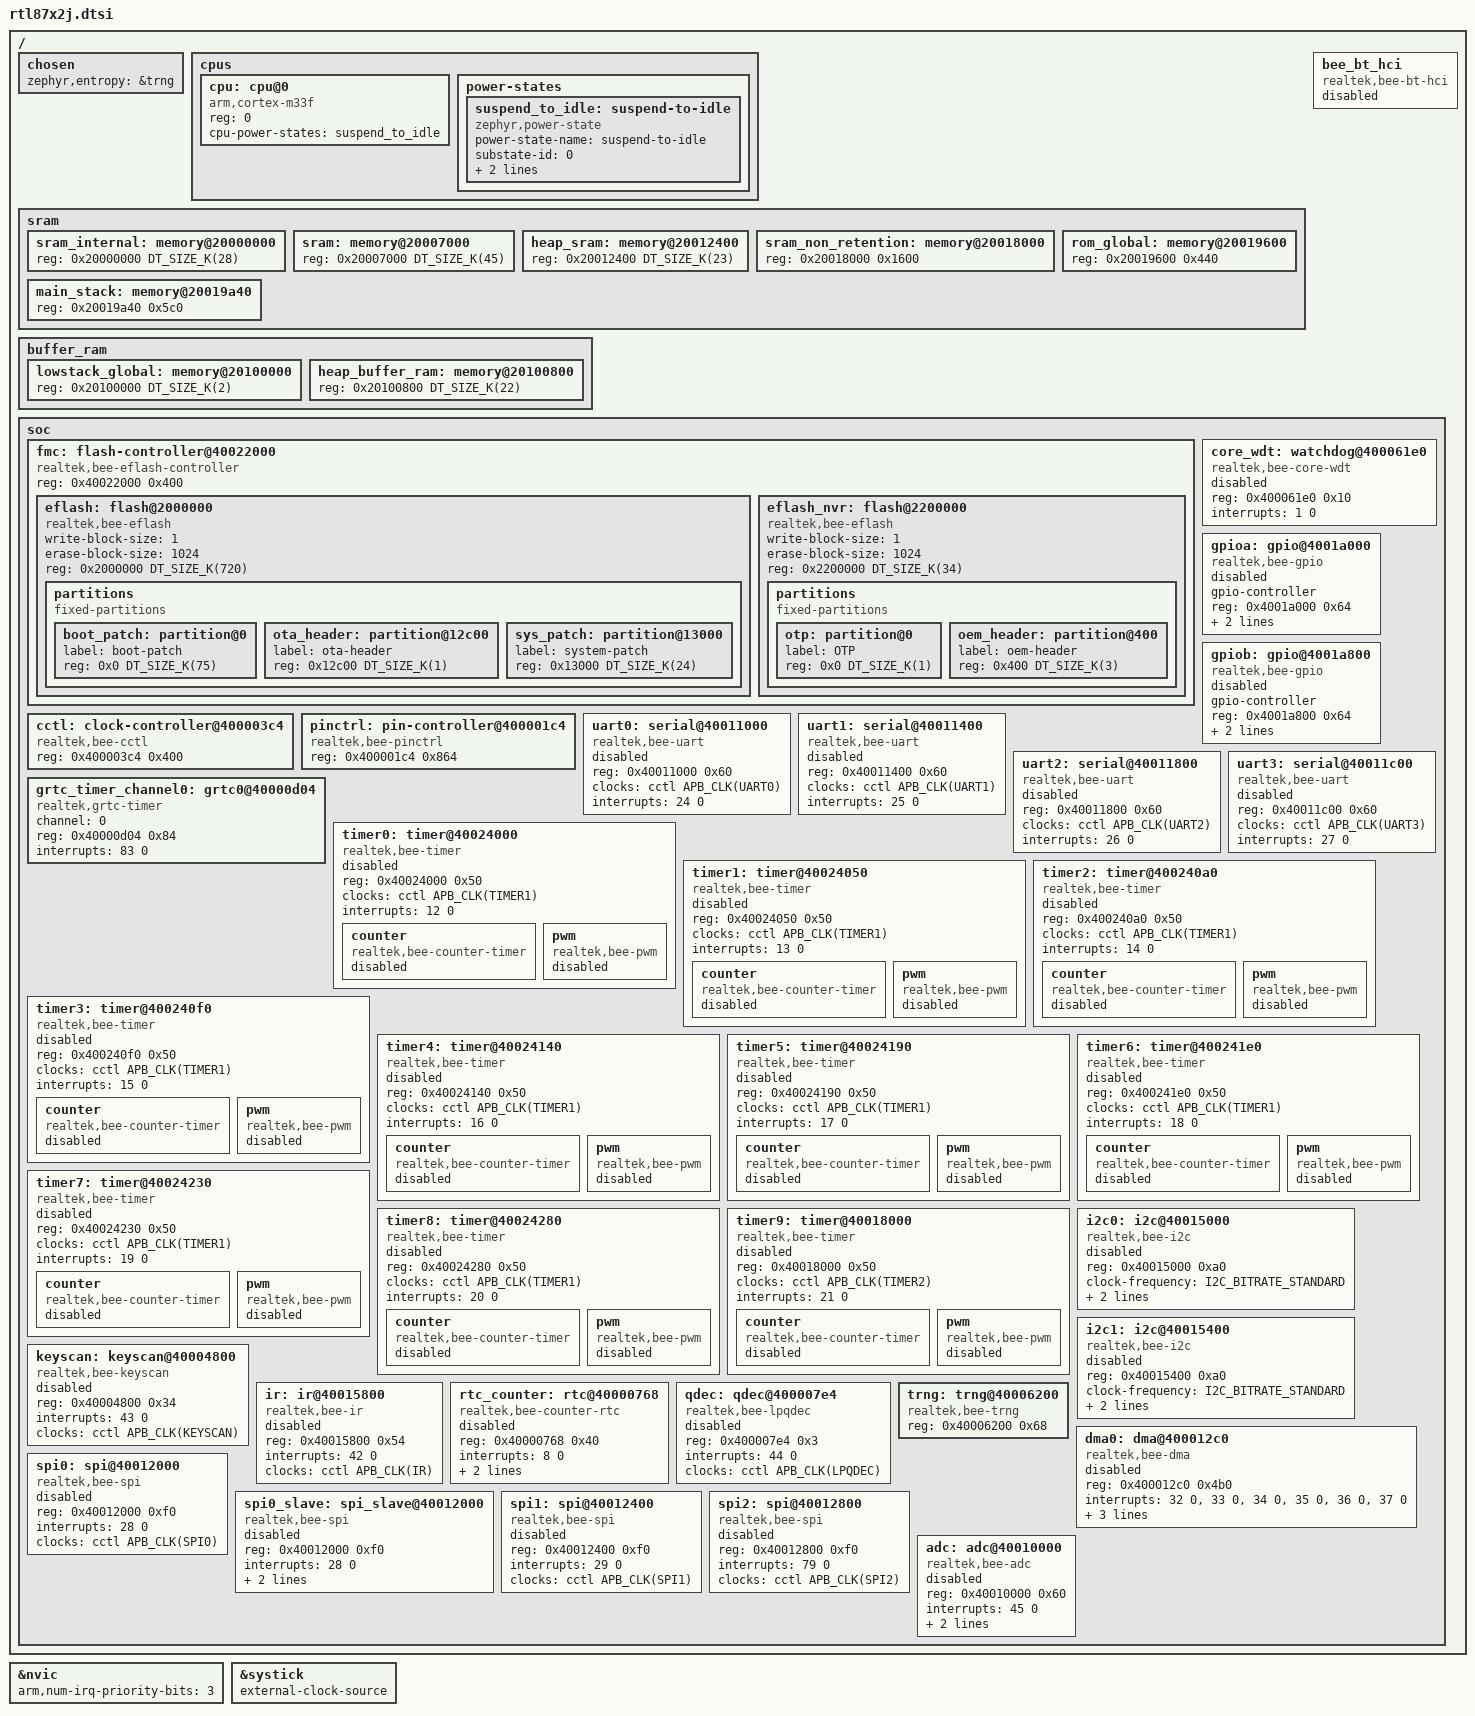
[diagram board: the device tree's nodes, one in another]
/*
 * Copyright (c) 2026, Realtek Semiconductor Corporation
 *
 * SPDX-License-Identifier: Apache-2.0
 */

#include <mem.h>
#include <arm/armv8-m.dtsi>
#include <dt-bindings/clock/rtl87x2j-clocks.h>
#include <zephyr/dt-bindings/gpio/gpio.h>
#include <zephyr/dt-bindings/i2c/i2c.h>
#include <zephyr/dt-bindings/adc/adc.h>

/ {
	chosen {
		zephyr,entropy = &trng;
	};

	cpus {
		#address-cells = <1>;
		#size-cells = <0>;

		cpu: cpu@0 {
			device_type = "cpu";
			compatible = "arm,cortex-m33f";
			reg = <0>;
			#address-cells = <1>;
			cpu-power-states = <&suspend_to_idle>;
			#size-cells = <1>;
		};

		power-states {
			suspend_to_idle: suspend-to-idle {
				compatible = "zephyr,power-state";
				power-state-name = "suspend-to-idle";
				substate-id = <0>;
				min-residency-us = <3000>;
				exit-latency-us = <2500>;
			};
		};
	};

	sram {
		#address-cells = <1>;
		#size-cells = <1>;

		/* 0x20000000 ~ 0x2001a000 */
		sram_internal: memory@20000000 {
			device_type = "internal sram region";
			reg = <0x20000000 DT_SIZE_K(28)>;
		};

		sram: memory@20007000 {
			device_type = "sram region";
			reg = <0x20007000 DT_SIZE_K(45)>;
		};

		heap_sram: memory@20012400 {
			device_type = "sram heap region";
			reg = <0x20012400 DT_SIZE_K(23)>;
		};

		sram_non_retention: memory@20018000 {
			device_type = "sram (non-retention) region";
			reg = <0x20018000 0x1600>;/* 5.5k */
		};

		rom_global: memory@20019600 {
			device_type = "rom globalregion";
			reg = <0x20019600 0x440>;/* 1K+64b */
		};

		main_stack: memory@20019a40 {
			device_type = "main stack region";
			reg = <0x20019a40 0x5c0>;/* 1.5k -64 b */
		};
	};

	buffer_ram {
		#address-cells = <1>;
		#size-cells = <1>;

		/* 0x20100000 ~ 0x20106000 */
		lowstack_global: memory@20100000 {
			device_type = "lowstack global region";
			reg = <0x20100000 DT_SIZE_K(2)>;
		};

		heap_buffer_ram: memory@20100800 {
			device_type = "heap buffer_ram region";
			reg = <0x20100800 DT_SIZE_K(22)>;
		};
	};

	bee_bt_hci: bee_bt_hci {
		compatible = "realtek,bee-bt-hci";
		status = "disabled";
	};

	soc {
		fmc: flash-controller@40022000 {
			compatible = "realtek,bee-eflash-controller";
			reg = <0x40022000 0x400>;
			#address-cells = <1>;
			#size-cells = <1>;
			status = "okay";

			eflash: flash@2000000 {
				compatible = "realtek,bee-eflash";
				#address-cells = <1>;
				#size-cells = <1>;
				write-block-size = <1>;
				erase-block-size = <1024>;
				reg = <0x2000000 DT_SIZE_K(720)>;
				ranges = <0x0 0x2000000 DT_SIZE_K(720)>;
				status = "okay";

				partitions {
					compatible = "fixed-partitions";
					#address-cells = <1>;
					#size-cells = <1>;

					/* 0x2000000-0x2017c00 is reserved for Realtek firmwares.
					 * Do not use.
					 */
					boot_patch: partition@0 {
						label = "boot-patch";
						reg = <0x0 DT_SIZE_K(75)>;
					};

					ota_header: partition@12c00 {
						label = "ota-header";
						reg = <0x12c00 DT_SIZE_K(1)>;
					};

					sys_patch: partition@13000 {
						label = "system-patch";
						reg = <0x13000 DT_SIZE_K(24)>;
					};
				};
			};

			eflash_nvr: flash@2200000 {
				compatible = "realtek,bee-eflash";
				#address-cells = <1>;
				#size-cells = <1>;
				write-block-size = <1>;
				erase-block-size = <1024>;
				reg = <0x2200000 DT_SIZE_K(34)>;
				ranges = <0x0 0x2200000 DT_SIZE_K(34)>;
				status = "okay";

				partitions {
					compatible = "fixed-partitions";
					#address-cells = <1>;
					#size-cells = <1>;

					/* 0x2200000-0x2201000 is reserved for Realtek firmwares.
					 * Do not use.
					 */
					otp: partition@0 {
						label = "OTP";
						reg = <0x0 DT_SIZE_K(1)>;
					};

					oem_header: partition@400 {
						label = "oem-header";
						reg = <0x400 DT_SIZE_K(3)>;
					};
				};
			};
		};

		cctl: clock-controller@400003c4 {
			compatible = "realtek,bee-cctl";
			reg = <0x400003c4 0x400>;
			#clock-cells = <1>;
			status = "okay";
		};

		core_wdt: watchdog@400061e0 {
			compatible = "realtek,bee-core-wdt";
			reg = <0x400061e0 0x10>;
			interrupts = <1 0>;
			status = "disabled";
		};

		pinctrl: pin-controller@400001c4 {
			compatible = "realtek,bee-pinctrl";
			reg = <0x400001c4 0x864>;
		};

		gpioa: gpio@4001a000 {
			compatible = "realtek,bee-gpio";
			gpio-controller;
			#gpio-cells = <2>;
			reg = <0x4001a000 0x64>;
			clocks = <&cctl APB_CLK(GPIOA)>;
			interrupts = <38 0>, <39 0>, <40 0>, <41 0>;
			status = "disabled";
		};

		gpiob: gpio@4001a800 {
			compatible = "realtek,bee-gpio";
			gpio-controller;
			#gpio-cells = <2>;
			reg = <0x4001a800 0x64>;
			clocks = <&cctl APB_CLK(GPIOB)>;
			interrupts = <75 0>, <76 0>, <77 0>;
			status = "disabled";
		};

		uart0: serial@40011000 {
			compatible = "realtek,bee-uart";
			reg = <0x40011000 0x60>;
			clocks = <&cctl APB_CLK(UART0)>;
			interrupts = <24 0>;
			status = "disabled";
		};

		uart1: serial@40011400 {
			compatible = "realtek,bee-uart";
			reg = <0x40011400 0x60>;
			clocks = <&cctl APB_CLK(UART1)>;
			interrupts = <25 0>;
			status = "disabled";
		};

		uart2: serial@40011800 {
			compatible = "realtek,bee-uart";
			reg = <0x40011800 0x60>;
			clocks = <&cctl APB_CLK(UART2)>;
			interrupts = <26 0>;
			status = "disabled";
		};

		/* uart3 is reserved for realtek bee internal log system. */
		uart3: serial@40011c00 {
			compatible = "realtek,bee-uart";
			reg = <0x40011c00 0x60>;
			clocks = <&cctl APB_CLK(UART3)>;
			interrupts = <27 0>;
			status = "disabled";
		};

		grtc_timer_channel0: grtc0@40000d04 {
			compatible = "realtek,grtc-timer";
			channel = <0>;
			reg = <0x40000d04 0x84>;
			interrupts = <83 0>;
			status = "okay";
		};

		timer0: timer@40024000 {
			compatible = "realtek,bee-timer", "realtek,bee-basic-timer";
			reg = <0x40024000 0x50>;
			clocks = <&cctl APB_CLK(TIMER1)>;
			interrupts = <12 0>;
			status = "disabled";

			counter {
				compatible = "realtek,bee-counter-timer";
				status = "disabled";
			};

			pwm {
				compatible = "realtek,bee-pwm";
				status = "disabled";
				#pwm-cells = <3>;
			};
		};

		timer1: timer@40024050 {
			compatible = "realtek,bee-timer", "realtek,bee-basic-timer";
			reg = <0x40024050 0x50>;
			clocks = <&cctl APB_CLK(TIMER1)>;
			interrupts = <13 0>;
			status = "disabled";

			counter {
				compatible = "realtek,bee-counter-timer";
				status = "disabled";
			};

			pwm {
				compatible = "realtek,bee-pwm";
				status = "disabled";
				#pwm-cells = <3>;
			};
		};

		timer2: timer@400240a0 {
			compatible = "realtek,bee-timer", "realtek,bee-basic-timer";
			reg = <0x400240a0 0x50>;
			clocks = <&cctl APB_CLK(TIMER1)>;
			interrupts = <14 0>;
			status = "disabled";

			counter {
				compatible = "realtek,bee-counter-timer";
				status = "disabled";
			};

			pwm {
				compatible = "realtek,bee-pwm";
				status = "disabled";
				#pwm-cells = <3>;
			};
		};

		timer3: timer@400240f0 {
			compatible = "realtek,bee-timer", "realtek,bee-basic-timer";
			reg = <0x400240f0 0x50>;
			clocks = <&cctl APB_CLK(TIMER1)>;
			interrupts = <15 0>;
			status = "disabled";

			counter {
				compatible = "realtek,bee-counter-timer";
				status = "disabled";
			};

			pwm {
				compatible = "realtek,bee-pwm";
				status = "disabled";
				#pwm-cells = <3>;
			};
		};

		timer4: timer@40024140 {
			compatible = "realtek,bee-timer", "realtek,bee-basic-timer";
			reg = <0x40024140 0x50>;
			clocks = <&cctl APB_CLK(TIMER1)>;
			interrupts = <16 0>;
			status = "disabled";

			counter {
				compatible = "realtek,bee-counter-timer";
				status = "disabled";
			};

			pwm {
				compatible = "realtek,bee-pwm";
				status = "disabled";
				#pwm-cells = <3>;
			};
		};

		timer5: timer@40024190 {
			compatible = "realtek,bee-timer", "realtek,bee-basic-timer";
			reg = <0x40024190 0x50>;
			clocks = <&cctl APB_CLK(TIMER1)>;
			interrupts = <17 0>;
			status = "disabled";

			counter {
				compatible = "realtek,bee-counter-timer";
				status = "disabled";
			};

			pwm {
				compatible = "realtek,bee-pwm";
				status = "disabled";
				#pwm-cells = <3>;
			};
		};

		timer6: timer@400241e0 {
			compatible = "realtek,bee-timer", "realtek,bee-basic-timer";
			reg = <0x400241e0 0x50>;
			clocks = <&cctl APB_CLK(TIMER1)>;
			interrupts = <18 0>;
			status = "disabled";

			counter {
				compatible = "realtek,bee-counter-timer";
				status = "disabled";
			};

			pwm {
				compatible = "realtek,bee-pwm";
				status = "disabled";
				#pwm-cells = <3>;
			};
		};

		timer7: timer@40024230 {
			compatible = "realtek,bee-timer", "realtek,bee-basic-timer";
			reg = <0x40024230 0x50>;
			clocks = <&cctl APB_CLK(TIMER1)>;
			interrupts = <19 0>;
			status = "disabled";

			counter {
				compatible = "realtek,bee-counter-timer";
				status = "disabled";
			};

			pwm {
				compatible = "realtek,bee-pwm";
				status = "disabled";
				#pwm-cells = <3>;
			};
		};

		timer8: timer@40024280 {
			compatible = "realtek,bee-timer", "realtek,bee-basic-timer";
			reg = <0x40024280 0x50>;
			clocks = <&cctl APB_CLK(TIMER1)>;
			interrupts = <20 0>;
			status = "disabled";

			counter {
				compatible = "realtek,bee-counter-timer";
				status = "disabled";
			};

			pwm {
				compatible = "realtek,bee-pwm";
				status = "disabled";
				#pwm-cells = <3>;
			};
		};

		timer9: timer@40018000 {
			compatible = "realtek,bee-timer", "realtek,bee-basic-timer";
			reg = <0x40018000 0x50>;
			clocks = <&cctl APB_CLK(TIMER2)>;
			interrupts = <21 0>;
			status = "disabled";

			counter {
				compatible = "realtek,bee-counter-timer";
				status = "disabled";
			};

			pwm {
				compatible = "realtek,bee-pwm";
				status = "disabled";
				#pwm-cells = <3>;
			};
		};

		i2c0: i2c@40015000 {
			compatible = "realtek,bee-i2c";
			reg = <0x40015000 0xa0>;
			clock-frequency = <I2C_BITRATE_STANDARD>;
			#address-cells = <1>;
			#size-cells = <0>;
			interrupts = <30 0>;
			clocks = <&cctl APB_CLK(I2C0)>;
			status = "disabled";
		};

		i2c1: i2c@40015400 {
			compatible = "realtek,bee-i2c";
			reg = <0x40015400 0xa0>;
			clock-frequency = <I2C_BITRATE_STANDARD>;
			#address-cells = <1>;
			#size-cells = <0>;
			interrupts = <31 0>;
			clocks = <&cctl APB_CLK(I2C1)>;
			status = "disabled";
		};

		keyscan: keyscan@40004800 {
			compatible = "realtek,bee-keyscan";
			reg = <0x40004800 0x34>;
			interrupts = <43 0>;
			clocks = <&cctl APB_CLK(KEYSCAN)>;
			status = "disabled";
		};

		ir: ir@40015800 {
			compatible = "realtek,bee-ir";
			reg = <0x40015800 0x54>;
			interrupts = <42 0>;
			clocks = <&cctl APB_CLK(IR)>;
			status = "disabled";
		};

		rtc_counter: rtc@40000768 {
			compatible = "realtek,bee-counter-rtc";
			reg = <0x40000768 0x40>;
			interrupts = <8 0>;
			channels = <4>;
			clocks = <&cctl APB_CLK(RTC)>;
			status = "disabled";
		};

		qdec: qdec@400007e4 {
			compatible = "realtek,bee-lpqdec";
			reg = <0x400007e4 0x3>;
			interrupts = <44 0>;
			clocks = <&cctl APB_CLK(LPQDEC)>;
			status = "disabled";
		};

		trng: trng@40006200 {
			compatible = "realtek,bee-trng";
			reg = <0x40006200 0x68>;
			status = "okay";
		};

		dma0: dma@400012c0 {
			compatible = "realtek,bee-dma";
			reg = <0x400012c0 0x4b0>;
			interrupts = <32 0>, <33 0>, <34 0>, <35 0>, <36 0>, <37 0>;
			dma-channels = <6>;
			clocks = <&cctl APB_CLK(DMA)>;
			dma-port = <0>;
			#dma-cells = <3>;
			status = "disabled";
		};

		spi0: spi@40012000 {
			compatible = "realtek,bee-spi";
			reg = <0x40012000 0xf0>;
			interrupts = <28 0>;
			clocks = <&cctl APB_CLK(SPI0)>;
			status = "disabled";
			#address-cells = <1>;
			#size-cells = <0>;
		};

		spi0_slave: spi_slave@40012000 {
			compatible = "realtek,bee-spi";
			reg = <0x40012000 0xf0>;
			interrupts = <28 0>;
			clocks = <&cctl APB_CLK(SPI0)>;
			status = "disabled";
			#address-cells = <1>;
			#size-cells = <0>;
			is-slave;
		};

		spi1: spi@40012400 {
			compatible = "realtek,bee-spi";
			reg = <0x40012400 0xf0>;
			interrupts = <29 0>;
			clocks = <&cctl APB_CLK(SPI1)>;
			status = "disabled";
			#address-cells = <1>;
			#size-cells = <0>;
		};

		spi2: spi@40012800 {
			compatible = "realtek,bee-spi";
			reg = <0x40012800 0xf0>;
			interrupts = <79 0>;
			clocks = <&cctl APB_CLK(SPI2)>;
			status = "disabled";
			#address-cells = <1>;
			#size-cells = <0>;
		};

		adc: adc@40010000 {
			compatible = "realtek,bee-adc";
			reg = <0x40010000 0x60>;
			interrupts = <45 0>;
			clocks = <&cctl APB_CLK(ADC)>;
			channels = <9>;
			status = "disabled";
			#io-channel-cells = <1>;
		};
	};
};

&nvic {
	arm,num-irq-priority-bits = <3>;
};

&systick {
	external-clock-source;
};
